AUTOSAR XML (schema 4-2-1)
standard types defined: boolean, float32, uint8, boolean_CompuMethod, boolean_DataConstr, float32_DataConstr, uint8_DataConstr
package /ComponentTypes
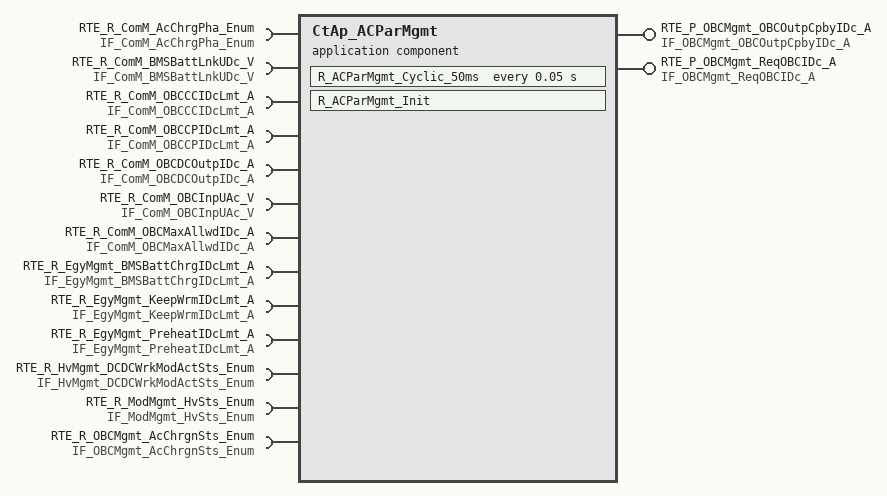
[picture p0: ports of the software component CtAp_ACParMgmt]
  application sw component type CtAp_ACParMgmt
    provide port RTE_P_OBCMgmt_OBCOutpCpbyIDc_A: nonqueued-sender-com-spec{data-element=tec_OBCMgmt_OBCOutpCpbyIDc_A, init-value=0}, provided-interface=IF_OBCMgmt_OBCOutpCpbyIDc_A
    provide port RTE_P_OBCMgmt_ReqOBCIDc_A: nonqueued-sender-com-spec{data-element=tec_OBCMgmt_ReqOBCIDc_A, init-value=0}, provided-interface=IF_OBCMgmt_ReqOBCIDc_A
    13 x require port:
      RTE_R_ComM_AcChrgPha_Enum: nonqueued-receiver-com-spec{data-element=tec_ComM_AcChrgPha_Enum, filter=data-filter-type=ALWAYS, init-value=0}, required-interface=IF_ComM_AcChrgPha_Enum
      RTE_R_ComM_BMSBattLnkUDc_V: nonqueued-receiver-com-spec{data-element=tec_ComM_BMSBattLnkUDc_V, filter=data-filter-type=ALWAYS, init-value=0}, required-interface=IF_ComM_BMSBattLnkUDc_V
      RTE_R_ComM_OBCCCIDcLmt_A: nonqueued-receiver-com-spec{data-element=tec_ComM_OBCCCIDcLmt_A, filter=data-filter-type=ALWAYS, init-value=0}, required-interface=IF_ComM_OBCCCIDcLmt_A
      RTE_R_ComM_OBCCPIDcLmt_A: nonqueued-receiver-com-spec{data-element=tec_ComM_OBCCPIDcLmt_A, filter=data-filter-type=ALWAYS, init-value=0}, required-interface=IF_ComM_OBCCPIDcLmt_A
      RTE_R_ComM_OBCDCOutpIDc_A: nonqueued-receiver-com-spec{data-element=tec_ComM_OBCDCOutpIDc_A, filter=data-filter-type=ALWAYS, init-value=0}, required-interface=IF_ComM_OBCDCOutpIDc_A
      RTE_R_ComM_OBCInpUAc_V: nonqueued-receiver-com-spec{data-element=tec_ComM_OBCInpUAc_V, filter=data-filter-type=ALWAYS, init-value=0}, required-interface=IF_ComM_OBCInpUAc_V
      RTE_R_ComM_OBCMaxAllwdIDc_A: nonqueued-receiver-com-spec{data-element=tec_ComM_OBCMaxAllwdIDc_A, filter=data-filter-type=ALWAYS, init-value=0}, required-interface=IF_ComM_OBCMaxAllwdIDc_A
      RTE_R_EgyMgmt_BMSBattChrgIDcLmt_A: nonqueued-receiver-com-spec{data-element=tec_EgyMgmt_BMSBattChrgIDcLmt_A, filter=data-filter-type=ALWAYS, init-value=0}, required-interface=IF_EgyMgmt_BMSBattChrgIDcLmt_A
      RTE_R_EgyMgmt_KeepWrmIDcLmt_A: nonqueued-receiver-com-spec{data-element=tec_EgyMgmt_KeepWrmIDcLmt_A, filter=data-filter-type=ALWAYS, init-value=0}, required-interface=IF_EgyMgmt_KeepWrmIDcLmt_A
      RTE_R_EgyMgmt_PreheatIDcLmt_A: nonqueued-receiver-com-spec{data-element=tec_EgyMgmt_PreheatIDcLmt_A, filter=data-filter-type=ALWAYS, init-value=0}, required-interface=IF_EgyMgmt_PreheatIDcLmt_A
      RTE_R_HvMgmt_DCDCWrkModActSts_Enum: nonqueued-receiver-com-spec{data-element=tec_HvMgmt_DCDCWrkModActSts_Enum, filter=data-filter-type=ALWAYS, init-value=0}, required-interface=IF_HvMgmt_DCDCWrkModActSts_Enum
      RTE_R_ModMgmt_HvSts_Enum: nonqueued-receiver-com-spec{data-element=tec_ModMgmt_HvSts_Enum, filter=data-filter-type=ALWAYS, init-value=0}, required-interface=IF_ModMgmt_HvSts_Enum
      RTE_R_OBCMgmt_AcChrgnSts_Enum: nonqueued-receiver-com-spec{data-element=tec_OBCMgmt_AcChrgnSts_Enum, filter=data-filter-type=ALWAYS, init-value=0}, required-interface=IF_OBCMgmt_AcChrgnSts_Enum
    behavior CtAp_ACParMgmt_InternalBehavior
      timing event TMT_R_ACParMgmt_Cyclic_50ms: start-on-event=R_ACParMgmt_Cyclic_50ms, period=0.05
      init event CtAp_ACParMgmt_InitEvent: start-on-event=R_ACParMgmt_Init
      runnable R_ACParMgmt_Cyclic_50ms
        data-receive-point-by-arguments:
          13 x access:
            REC_RTE_R_ComM_AcChrgPha_Enum_tec_ComM_AcChrgPha_Enum: accessed-variable=RTE_R_ComM_AcChrgPha_Enum.tec_ComM_AcChrgPha_Enum
            REC_RTE_R_ComM_BMSBattLnkUDc_V_tec_ComM_BMSBattLnkUDc_V: accessed-variable=RTE_R_ComM_BMSBattLnkUDc_V.tec_ComM_BMSBattLnkUDc_V
            REC_RTE_R_ComM_OBCCCIDcLmt_A_tec_ComM_OBCCCIDcLmt_A: accessed-variable=RTE_R_ComM_OBCCCIDcLmt_A.tec_ComM_OBCCCIDcLmt_A
            REC_RTE_R_ComM_OBCCPIDcLmt_A_tec_ComM_OBCCPIDcLmt_A: accessed-variable=RTE_R_ComM_OBCCPIDcLmt_A.tec_ComM_OBCCPIDcLmt_A
            REC_RTE_R_ComM_OBCDCOutpIDc_A_tec_ComM_OBCDCOutpIDc_A: accessed-variable=RTE_R_ComM_OBCDCOutpIDc_A.tec_ComM_OBCDCOutpIDc_A
            REC_RTE_R_ComM_OBCInpUAc_V_tec_ComM_OBCInpUAc_V: accessed-variable=RTE_R_ComM_OBCInpUAc_V.tec_ComM_OBCInpUAc_V
            REC_RTE_R_ComM_OBCMaxAllwdIDc_A_tec_ComM_OBCMaxAllwdIDc_A: accessed-variable=RTE_R_ComM_OBCMaxAllwdIDc_A.tec_ComM_OBCMaxAllwdIDc_A
            REC_RTE_R_EgyMgmt_BMSBattChrgIDcLmt_A_tec_EgyMgmt_BMSBattChrgIDcLmt_A: accessed-variable=RTE_R_EgyMgmt_BMSBattChrgIDcLmt_A.tec_EgyMgmt_BMSBattChrgIDcLmt_A
            REC_RTE_R_EgyMgmt_KeepWrmIDcLmt_A_tec_EgyMgmt_KeepWrmIDcLmt_A: accessed-variable=RTE_R_EgyMgmt_KeepWrmIDcLmt_A.tec_EgyMgmt_KeepWrmIDcLmt_A
            REC_RTE_R_EgyMgmt_PreheatIDcLmt_A_tec_EgyMgmt_PreheatIDcLmt_A: accessed-variable=RTE_R_EgyMgmt_PreheatIDcLmt_A.tec_EgyMgmt_PreheatIDcLmt_A
            REC_RTE_R_HvMgmt_DCDCWrkModActSts_Enum_tec_HvMgmt_DCDCWrkModActSts_Enum: accessed-variable=RTE_R_HvMgmt_DCDCWrkModActSts_Enum.tec_HvMgmt_DCDCWrkModActSts_Enum
            REC_RTE_R_ModMgmt_HvSts_Enum_tec_ModMgmt_HvSts_Enum: accessed-variable=RTE_R_ModMgmt_HvSts_Enum.tec_ModMgmt_HvSts_Enum
            REC_RTE_R_OBCMgmt_AcChrgnSts_Enum_tec_OBCMgmt_AcChrgnSts_Enum: accessed-variable=RTE_R_OBCMgmt_AcChrgnSts_Enum.tec_OBCMgmt_AcChrgnSts_Enum
        data-send-points:
          access SEND_RTE_P_OBCMgmt_OBCOutpCpbyIDc_A_tec_OBCMgmt_OBCOutpCpbyIDc_A: accessed-variable=RTE_P_OBCMgmt_OBCOutpCpbyIDc_A.tec_OBCMgmt_OBCOutpCpbyIDc_A
          access SEND_RTE_P_OBCMgmt_ReqOBCIDc_A_tec_OBCMgmt_ReqOBCIDc_A: accessed-variable=RTE_P_OBCMgmt_ReqOBCIDc_A.tec_OBCMgmt_ReqOBCIDc_A
      runnable R_ACParMgmt_Init
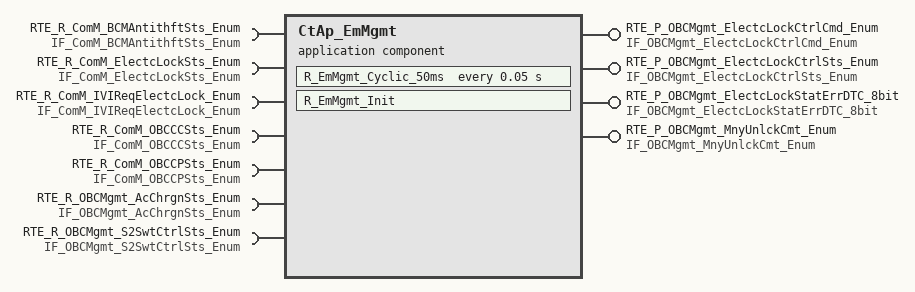
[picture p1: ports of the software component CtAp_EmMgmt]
  application sw component type CtAp_EmMgmt
    4 x provide port:
      RTE_P_OBCMgmt_ElectcLockCtrlCmd_Enum: nonqueued-sender-com-spec{data-element=tec_OBCMgmt_ElectcLockCtrlCmd_Enum, init-value=0}, provided-interface=IF_OBCMgmt_ElectcLockCtrlCmd_Enum
      RTE_P_OBCMgmt_ElectcLockCtrlSts_Enum: nonqueued-sender-com-spec{data-element=tec_OBCMgmt_ElectcLockCtrlSts_Enum, init-value=0}, provided-interface=IF_OBCMgmt_ElectcLockCtrlSts_Enum
      RTE_P_OBCMgmt_ElectcLockStatErrDTC_8bit: nonqueued-sender-com-spec{data-element=tec_OBCMgmt_ElectcLockStatErrDTC_8bit, init-value=0}, provided-interface=IF_OBCMgmt_ElectcLockStatErrDTC_8bit
      RTE_P_OBCMgmt_MnyUnlckCmt_Enum: nonqueued-sender-com-spec{data-element=tec_OBCMgmt_MnyUnlckCmt_Enum, init-value=0}, provided-interface=IF_OBCMgmt_MnyUnlckCmt_Enum
    7 x require port:
      RTE_R_ComM_BCMAntithftSts_Enum: nonqueued-receiver-com-spec{data-element=tec_ComM_BCMAntithftSts_Enum, filter=data-filter-type=ALWAYS, init-value=0}, required-interface=IF_ComM_BCMAntithftSts_Enum
      RTE_R_ComM_ElectcLockSts_Enum: nonqueued-receiver-com-spec{data-element=tec_ComM_ElectcLockSts_Enum, filter=data-filter-type=ALWAYS, init-value=0}, required-interface=IF_ComM_ElectcLockSts_Enum
      RTE_R_ComM_IVIReqElectcLock_Enum: nonqueued-receiver-com-spec{data-element=tec_ComM_IVIReqElectcLock_Enum, filter=data-filter-type=ALWAYS, init-value=0}, required-interface=IF_ComM_IVIReqElectcLock_Enum
      RTE_R_ComM_OBCCCSts_Enum: nonqueued-receiver-com-spec{data-element=tec_ComM_OBCCCSts_Enum, filter=data-filter-type=ALWAYS, init-value=0}, required-interface=IF_ComM_OBCCCSts_Enum
      RTE_R_ComM_OBCCPSts_Enum: nonqueued-receiver-com-spec{data-element=tec_ComM_OBCCPSts_Enum, filter=data-filter-type=ALWAYS, init-value=0}, required-interface=IF_ComM_OBCCPSts_Enum
      RTE_R_OBCMgmt_AcChrgnSts_Enum: nonqueued-receiver-com-spec{data-element=tec_OBCMgmt_AcChrgnSts_Enum, filter=data-filter-type=ALWAYS, init-value=0}, required-interface=IF_OBCMgmt_AcChrgnSts_Enum
      RTE_R_OBCMgmt_S2SwtCtrlSts_Enum: nonqueued-receiver-com-spec{data-element=tec_OBCMgmt_S2SwtCtrlSts_Enum, filter=data-filter-type=ALWAYS, init-value=0}, required-interface=IF_OBCMgmt_S2SwtCtrlSts_Enum
    behavior CtAp_EmMgmt_InternalBehavior
      timing event TMT_R_EmMgmt_Cyclic_50ms: start-on-event=R_EmMgmt_Cyclic_50ms, period=0.05
      init event CtAp_EmMgmt_InitEvent: start-on-event=R_EmMgmt_Init
      runnable R_EmMgmt_Cyclic_50ms
        data-receive-point-by-arguments:
          7 x access:
            REC_RTE_R_ComM_BCMAntithftSts_Enum_tec_ComM_BCMAntithftSts_Enum: accessed-variable=RTE_R_ComM_BCMAntithftSts_Enum.tec_ComM_BCMAntithftSts_Enum
            REC_RTE_R_ComM_ElectcLockSts_Enum_tec_ComM_ElectcLockSts_Enum: accessed-variable=RTE_R_ComM_ElectcLockSts_Enum.tec_ComM_ElectcLockSts_Enum
            REC_RTE_R_ComM_IVIReqElectcLock_Enum_tec_ComM_IVIReqElectcLock_Enum: accessed-variable=RTE_R_ComM_IVIReqElectcLock_Enum.tec_ComM_IVIReqElectcLock_Enum
            REC_RTE_R_ComM_OBCCCSts_Enum_tec_ComM_OBCCCSts_Enum: accessed-variable=RTE_R_ComM_OBCCCSts_Enum.tec_ComM_OBCCCSts_Enum
            REC_RTE_R_ComM_OBCCPSts_Enum_tec_ComM_OBCCPSts_Enum: accessed-variable=RTE_R_ComM_OBCCPSts_Enum.tec_ComM_OBCCPSts_Enum
            REC_RTE_R_OBCMgmt_AcChrgnSts_Enum_tec_OBCMgmt_AcChrgnSts_Enum: accessed-variable=RTE_R_OBCMgmt_AcChrgnSts_Enum.tec_OBCMgmt_AcChrgnSts_Enum
            REC_RTE_R_OBCMgmt_S2SwtCtrlSts_Enum_tec_OBCMgmt_S2SwtCtrlSts_Enum: accessed-variable=RTE_R_OBCMgmt_S2SwtCtrlSts_Enum.tec_OBCMgmt_S2SwtCtrlSts_Enum
        data-send-points:
          4 x access:
            SEND_RTE_P_OBCMgmt_ElectcLockCtrlCmd_Enum_tec_OBCMgmt_ElectcLockCtrlCmd_Enum: accessed-variable=RTE_P_OBCMgmt_ElectcLockCtrlCmd_Enum.tec_OBCMgmt_ElectcLockCtrlCmd_Enum
            SEND_RTE_P_OBCMgmt_ElectcLockCtrlSts_Enum_tec_OBCMgmt_ElectcLockCtrlSts_Enum: accessed-variable=RTE_P_OBCMgmt_ElectcLockCtrlSts_Enum.tec_OBCMgmt_ElectcLockCtrlSts_Enum
            SEND_RTE_P_OBCMgmt_ElectcLockStatErrDTC_8bit_tec_OBCMgmt_ElectcLockStatErrDTC_8bit: accessed-variable=RTE_P_OBCMgmt_ElectcLockStatErrDTC_8bit.tec_OBCMgmt_ElectcLockStatErrDTC_8bit
            SEND_RTE_P_OBCMgmt_MnyUnlckCmt_Enum_tec_OBCMgmt_MnyUnlckCmt_Enum: accessed-variable=RTE_P_OBCMgmt_MnyUnlckCmt_Enum.tec_OBCMgmt_MnyUnlckCmt_Enum
      runnable R_EmMgmt_Init
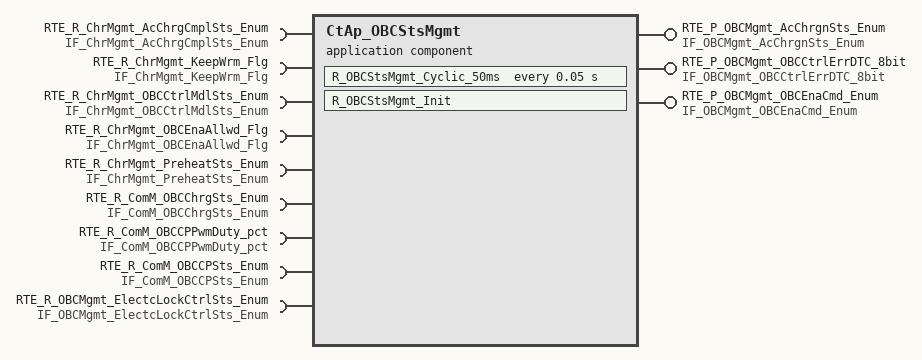
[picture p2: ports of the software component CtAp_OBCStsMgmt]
  application sw component type CtAp_OBCStsMgmt
    provide port RTE_P_OBCMgmt_AcChrgnSts_Enum: nonqueued-sender-com-spec{data-element=tec_OBCMgmt_AcChrgnSts_Enum, init-value=0}, provided-interface=IF_OBCMgmt_AcChrgnSts_Enum
    provide port RTE_P_OBCMgmt_OBCCtrlErrDTC_8bit: nonqueued-sender-com-spec{data-element=tec_OBCMgmt_OBCCtrlErrDTC_8bit, init-value=0}, provided-interface=IF_OBCMgmt_OBCCtrlErrDTC_8bit
    provide port RTE_P_OBCMgmt_OBCEnaCmd_Enum: nonqueued-sender-com-spec{data-element=tec_OBCMgmt_OBCEnaCmd_Enum, init-value=0}, provided-interface=IF_OBCMgmt_OBCEnaCmd_Enum
    9 x require port:
      RTE_R_ChrMgmt_AcChrgCmplSts_Enum: nonqueued-receiver-com-spec{data-element=tec_ChrMgmt_AcChrgCmplSts_Enum, filter=data-filter-type=ALWAYS, init-value=0}, required-interface=IF_ChrMgmt_AcChrgCmplSts_Enum
      RTE_R_ChrMgmt_KeepWrm_Flg: nonqueued-receiver-com-spec{data-element=tec_ChrMgmt_KeepWrm_Flg, filter=data-filter-type=ALWAYS, init-value=0}, required-interface=IF_ChrMgmt_KeepWrm_Flg
      RTE_R_ChrMgmt_OBCCtrlMdlSts_Enum: nonqueued-receiver-com-spec{data-element=tec_ChrMgmt_OBCCtrlMdlSts_Enum, filter=data-filter-type=ALWAYS, init-value=0}, required-interface=IF_ChrMgmt_OBCCtrlMdlSts_Enum
      RTE_R_ChrMgmt_OBCEnaAllwd_Flg: nonqueued-receiver-com-spec{data-element=tec_ChrMgmt_OBCEnaAllwd_Flg, filter=data-filter-type=ALWAYS, init-value=0}, required-interface=IF_ChrMgmt_OBCEnaAllwd_Flg
      RTE_R_ChrMgmt_PreheatSts_Enum: nonqueued-receiver-com-spec{data-element=tec_ChrMgmt_PreheatSts_Enum, filter=data-filter-type=ALWAYS, init-value=0}, required-interface=IF_ChrMgmt_PreheatSts_Enum
      RTE_R_ComM_OBCChrgSts_Enum: nonqueued-receiver-com-spec{data-element=tec_ComM_OBCChrgSts_Enum, filter=data-filter-type=ALWAYS, init-value=0}, required-interface=IF_ComM_OBCChrgSts_Enum
      RTE_R_ComM_OBCCPPwmDuty_pct: nonqueued-receiver-com-spec{data-element=tec_ComM_OBCCPPwmDuty_pct, filter=data-filter-type=ALWAYS, init-value=0}, required-interface=IF_ComM_OBCCPPwmDuty_pct
      RTE_R_ComM_OBCCPSts_Enum: nonqueued-receiver-com-spec{data-element=tec_ComM_OBCCPSts_Enum, filter=data-filter-type=ALWAYS, init-value=0}, required-interface=IF_ComM_OBCCPSts_Enum
      RTE_R_OBCMgmt_ElectcLockCtrlSts_Enum: nonqueued-receiver-com-spec{data-element=tec_OBCMgmt_ElectcLockCtrlSts_Enum, filter=data-filter-type=ALWAYS, init-value=0}, required-interface=IF_OBCMgmt_ElectcLockCtrlSts_Enum
    behavior CtAp_OBCStsMgmt_InternalBehavior
      timing event TMT_R_OBCStsMgmt_Cyclic_50ms: start-on-event=R_OBCStsMgmt_Cyclic_50ms, period=0.05
      init event CtAp_OBCStsMgmt_InitEvent: start-on-event=R_OBCStsMgmt_Init
      runnable R_OBCStsMgmt_Cyclic_50ms
        data-receive-point-by-arguments:
          9 x access:
            REC_RTE_R_ChrMgmt_AcChrgCmplSts_Enum_tec_ChrMgmt_AcChrgCmplSts_Enum: accessed-variable=RTE_R_ChrMgmt_AcChrgCmplSts_Enum.tec_ChrMgmt_AcChrgCmplSts_Enum
            REC_RTE_R_ChrMgmt_KeepWrm_Flg_tec_ChrMgmt_KeepWrm_Flg: accessed-variable=RTE_R_ChrMgmt_KeepWrm_Flg.tec_ChrMgmt_KeepWrm_Flg
            REC_RTE_R_ChrMgmt_OBCCtrlMdlSts_Enum_tec_ChrMgmt_OBCCtrlMdlSts_Enum: accessed-variable=RTE_R_ChrMgmt_OBCCtrlMdlSts_Enum.tec_ChrMgmt_OBCCtrlMdlSts_Enum
            REC_RTE_R_ChrMgmt_OBCEnaAllwd_Flg_tec_ChrMgmt_OBCEnaAllwd_Flg: accessed-variable=RTE_R_ChrMgmt_OBCEnaAllwd_Flg.tec_ChrMgmt_OBCEnaAllwd_Flg
            REC_RTE_R_ChrMgmt_PreheatSts_Enum_tec_ChrMgmt_PreheatSts_Enum: accessed-variable=RTE_R_ChrMgmt_PreheatSts_Enum.tec_ChrMgmt_PreheatSts_Enum
            REC_RTE_R_ComM_OBCChrgSts_Enum_tec_ComM_OBCChrgSts_Enum: accessed-variable=RTE_R_ComM_OBCChrgSts_Enum.tec_ComM_OBCChrgSts_Enum
            REC_RTE_R_ComM_OBCCPPwmDuty_pct_tec_ComM_OBCCPPwmDuty_pct: accessed-variable=RTE_R_ComM_OBCCPPwmDuty_pct.tec_ComM_OBCCPPwmDuty_pct
            REC_RTE_R_ComM_OBCCPSts_Enum_tec_ComM_OBCCPSts_Enum: accessed-variable=RTE_R_ComM_OBCCPSts_Enum.tec_ComM_OBCCPSts_Enum
            REC_RTE_R_OBCMgmt_ElectcLockCtrlSts_Enum_tec_OBCMgmt_ElectcLockCtrlSts_Enum: accessed-variable=RTE_R_OBCMgmt_ElectcLockCtrlSts_Enum.tec_OBCMgmt_ElectcLockCtrlSts_Enum
        data-send-points:
          access SEND_RTE_P_OBCMgmt_AcChrgnSts_Enum_tec_OBCMgmt_AcChrgnSts_Enum: accessed-variable=RTE_P_OBCMgmt_AcChrgnSts_Enum.tec_OBCMgmt_AcChrgnSts_Enum
          access SEND_RTE_P_OBCMgmt_OBCCtrlErrDTC_8bit_tec_OBCMgmt_OBCCtrlErrDTC_8bit: accessed-variable=RTE_P_OBCMgmt_OBCCtrlErrDTC_8bit.tec_OBCMgmt_OBCCtrlErrDTC_8bit
          access SEND_RTE_P_OBCMgmt_OBCEnaCmd_Enum_tec_OBCMgmt_OBCEnaCmd_Enum: accessed-variable=RTE_P_OBCMgmt_OBCEnaCmd_Enum.tec_OBCMgmt_OBCEnaCmd_Enum
      runnable R_OBCStsMgmt_Init
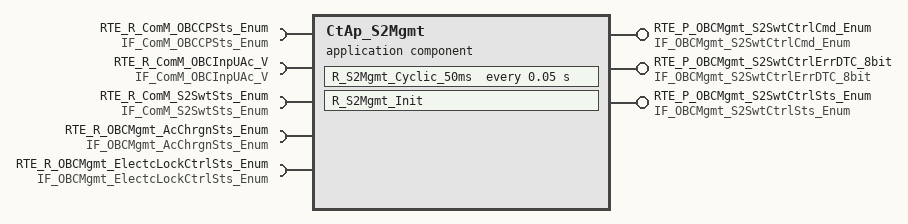
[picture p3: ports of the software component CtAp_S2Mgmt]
  application sw component type CtAp_S2Mgmt
    provide port RTE_P_OBCMgmt_S2SwtCtrlCmd_Enum: nonqueued-sender-com-spec{data-element=tec_OBCMgmt_S2SwtCtrlCmd_Enum, init-value=0}, provided-interface=IF_OBCMgmt_S2SwtCtrlCmd_Enum
    provide port RTE_P_OBCMgmt_S2SwtCtrlErrDTC_8bit: nonqueued-sender-com-spec{data-element=tec_OBCMgmt_S2SwtCtrlErrDTC_8bit, init-value=0}, provided-interface=IF_OBCMgmt_S2SwtCtrlErrDTC_8bit
    provide port RTE_P_OBCMgmt_S2SwtCtrlSts_Enum: nonqueued-sender-com-spec{data-element=tec_OBCMgmt_S2SwtCtrlSts_Enum, init-value=0}, provided-interface=IF_OBCMgmt_S2SwtCtrlSts_Enum
    5 x require port:
      RTE_R_ComM_OBCCPSts_Enum: nonqueued-receiver-com-spec{data-element=tec_ComM_OBCCPSts_Enum, filter=data-filter-type=ALWAYS, init-value=0}, required-interface=IF_ComM_OBCCPSts_Enum
      RTE_R_ComM_OBCInpUAc_V: nonqueued-receiver-com-spec{data-element=tec_ComM_OBCInpUAc_V, filter=data-filter-type=ALWAYS, init-value=0}, required-interface=IF_ComM_OBCInpUAc_V
      RTE_R_ComM_S2SwtSts_Enum: nonqueued-receiver-com-spec{data-element=tec_ComM_S2SwtSts_Enum, filter=data-filter-type=ALWAYS, init-value=0}, required-interface=IF_ComM_S2SwtSts_Enum
      RTE_R_OBCMgmt_AcChrgnSts_Enum: nonqueued-receiver-com-spec{data-element=tec_OBCMgmt_AcChrgnSts_Enum, filter=data-filter-type=ALWAYS, init-value=0}, required-interface=IF_OBCMgmt_AcChrgnSts_Enum
      RTE_R_OBCMgmt_ElectcLockCtrlSts_Enum: nonqueued-receiver-com-spec{data-element=tec_OBCMgmt_ElectcLockCtrlSts_Enum, filter=data-filter-type=ALWAYS, init-value=0}, required-interface=IF_OBCMgmt_ElectcLockCtrlSts_Enum
    behavior CtAp_S2Mgmt_InternalBehavior
      timing event TMT_R_S2Mgmt_Cyclic_50ms: start-on-event=R_S2Mgmt_Cyclic_50ms, period=0.05
      init event CtAp_S2Mgmt_InitEvent: start-on-event=R_S2Mgmt_Init
      runnable R_S2Mgmt_Cyclic_50ms
        data-receive-point-by-arguments:
          5 x access:
            REC_RTE_R_ComM_OBCCPSts_Enum_tec_ComM_OBCCPSts_Enum: accessed-variable=RTE_R_ComM_OBCCPSts_Enum.tec_ComM_OBCCPSts_Enum
            REC_RTE_R_ComM_OBCInpUAc_V_tec_ComM_OBCInpUAc_V: accessed-variable=RTE_R_ComM_OBCInpUAc_V.tec_ComM_OBCInpUAc_V
            REC_RTE_R_ComM_S2SwtSts_Enum_tec_ComM_S2SwtSts_Enum: accessed-variable=RTE_R_ComM_S2SwtSts_Enum.tec_ComM_S2SwtSts_Enum
            REC_RTE_R_OBCMgmt_AcChrgnSts_Enum_tec_OBCMgmt_AcChrgnSts_Enum: accessed-variable=RTE_R_OBCMgmt_AcChrgnSts_Enum.tec_OBCMgmt_AcChrgnSts_Enum
            REC_RTE_R_OBCMgmt_ElectcLockCtrlSts_Enum_tec_OBCMgmt_ElectcLockCtrlSts_Enum: accessed-variable=RTE_R_OBCMgmt_ElectcLockCtrlSts_Enum.tec_OBCMgmt_ElectcLockCtrlSts_Enum
        data-send-points:
          access SEND_RTE_P_OBCMgmt_S2SwtCtrlCmd_Enum_tec_OBCMgmt_S2SwtCtrlCmd_Enum: accessed-variable=RTE_P_OBCMgmt_S2SwtCtrlCmd_Enum.tec_OBCMgmt_S2SwtCtrlCmd_Enum
          access SEND_RTE_P_OBCMgmt_S2SwtCtrlErrDTC_8bit_tec_OBCMgmt_S2SwtCtrlErrDTC_8bit: accessed-variable=RTE_P_OBCMgmt_S2SwtCtrlErrDTC_8bit.tec_OBCMgmt_S2SwtCtrlErrDTC_8bit
          access SEND_RTE_P_OBCMgmt_S2SwtCtrlSts_Enum_tec_OBCMgmt_S2SwtCtrlSts_Enum: accessed-variable=RTE_P_OBCMgmt_S2SwtCtrlSts_Enum.tec_OBCMgmt_S2SwtCtrlSts_Enum
      runnable R_S2Mgmt_Init
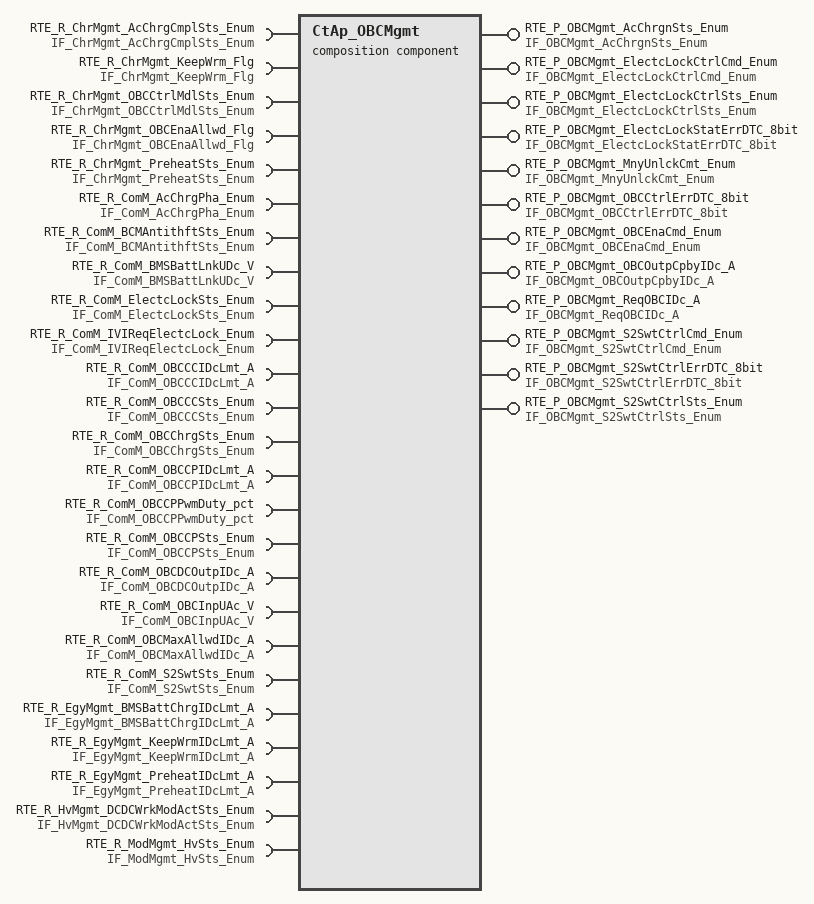
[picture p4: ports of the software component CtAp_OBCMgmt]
  composition sw component type CtAp_OBCMgmt
    12 x provide port:
      RTE_P_OBCMgmt_AcChrgnSts_Enum: nonqueued-sender-com-spec{data-element=tec_OBCMgmt_AcChrgnSts_Enum, init-value=0}, provided-interface=IF_OBCMgmt_AcChrgnSts_Enum
      RTE_P_OBCMgmt_ElectcLockCtrlCmd_Enum: nonqueued-sender-com-spec{data-element=tec_OBCMgmt_ElectcLockCtrlCmd_Enum, init-value=0}, provided-interface=IF_OBCMgmt_ElectcLockCtrlCmd_Enum
      RTE_P_OBCMgmt_ElectcLockCtrlSts_Enum: nonqueued-sender-com-spec{data-element=tec_OBCMgmt_ElectcLockCtrlSts_Enum, init-value=0}, provided-interface=IF_OBCMgmt_ElectcLockCtrlSts_Enum
      RTE_P_OBCMgmt_ElectcLockStatErrDTC_8bit: nonqueued-sender-com-spec{data-element=tec_OBCMgmt_ElectcLockStatErrDTC_8bit, init-value=0}, provided-interface=IF_OBCMgmt_ElectcLockStatErrDTC_8bit
      RTE_P_OBCMgmt_MnyUnlckCmt_Enum: nonqueued-sender-com-spec{data-element=tec_OBCMgmt_MnyUnlckCmt_Enum, init-value=0}, provided-interface=IF_OBCMgmt_MnyUnlckCmt_Enum
      RTE_P_OBCMgmt_OBCCtrlErrDTC_8bit: nonqueued-sender-com-spec{data-element=tec_OBCMgmt_OBCCtrlErrDTC_8bit, init-value=0}, provided-interface=IF_OBCMgmt_OBCCtrlErrDTC_8bit
      RTE_P_OBCMgmt_OBCEnaCmd_Enum: nonqueued-sender-com-spec{data-element=tec_OBCMgmt_OBCEnaCmd_Enum, init-value=0}, provided-interface=IF_OBCMgmt_OBCEnaCmd_Enum
      RTE_P_OBCMgmt_OBCOutpCpbyIDc_A: nonqueued-sender-com-spec{data-element=tec_OBCMgmt_OBCOutpCpbyIDc_A, init-value=0}, provided-interface=IF_OBCMgmt_OBCOutpCpbyIDc_A
      RTE_P_OBCMgmt_ReqOBCIDc_A: nonqueued-sender-com-spec{data-element=tec_OBCMgmt_ReqOBCIDc_A, init-value=0}, provided-interface=IF_OBCMgmt_ReqOBCIDc_A
      RTE_P_OBCMgmt_S2SwtCtrlCmd_Enum: nonqueued-sender-com-spec{data-element=tec_OBCMgmt_S2SwtCtrlCmd_Enum, init-value=0}, provided-interface=IF_OBCMgmt_S2SwtCtrlCmd_Enum
      RTE_P_OBCMgmt_S2SwtCtrlErrDTC_8bit: nonqueued-sender-com-spec{data-element=tec_OBCMgmt_S2SwtCtrlErrDTC_8bit, init-value=0}, provided-interface=IF_OBCMgmt_S2SwtCtrlErrDTC_8bit
      RTE_P_OBCMgmt_S2SwtCtrlSts_Enum: nonqueued-sender-com-spec{data-element=tec_OBCMgmt_S2SwtCtrlSts_Enum, init-value=0}, provided-interface=IF_OBCMgmt_S2SwtCtrlSts_Enum
    25 x require port:
      RTE_R_ChrMgmt_AcChrgCmplSts_Enum: nonqueued-receiver-com-spec{data-element=tec_ChrMgmt_AcChrgCmplSts_Enum, filter=data-filter-type=ALWAYS, init-value=0}, required-interface=IF_ChrMgmt_AcChrgCmplSts_Enum
      RTE_R_ChrMgmt_KeepWrm_Flg: nonqueued-receiver-com-spec{data-element=tec_ChrMgmt_KeepWrm_Flg, filter=data-filter-type=ALWAYS, init-value=0}, required-interface=IF_ChrMgmt_KeepWrm_Flg
      RTE_R_ChrMgmt_OBCCtrlMdlSts_Enum: nonqueued-receiver-com-spec{data-element=tec_ChrMgmt_OBCCtrlMdlSts_Enum, filter=data-filter-type=ALWAYS, init-value=0}, required-interface=IF_ChrMgmt_OBCCtrlMdlSts_Enum
      RTE_R_ChrMgmt_OBCEnaAllwd_Flg: nonqueued-receiver-com-spec{data-element=tec_ChrMgmt_OBCEnaAllwd_Flg, filter=data-filter-type=ALWAYS, init-value=0}, required-interface=IF_ChrMgmt_OBCEnaAllwd_Flg
      RTE_R_ChrMgmt_PreheatSts_Enum: nonqueued-receiver-com-spec{data-element=tec_ChrMgmt_PreheatSts_Enum, filter=data-filter-type=ALWAYS, init-value=0}, required-interface=IF_ChrMgmt_PreheatSts_Enum
      RTE_R_ComM_AcChrgPha_Enum: nonqueued-receiver-com-spec{data-element=tec_ComM_AcChrgPha_Enum, filter=data-filter-type=ALWAYS, init-value=0}, required-interface=IF_ComM_AcChrgPha_Enum
      RTE_R_ComM_BCMAntithftSts_Enum: nonqueued-receiver-com-spec{data-element=tec_ComM_BCMAntithftSts_Enum, filter=data-filter-type=ALWAYS, init-value=0}, required-interface=IF_ComM_BCMAntithftSts_Enum
      RTE_R_ComM_BMSBattLnkUDc_V: nonqueued-receiver-com-spec{data-element=tec_ComM_BMSBattLnkUDc_V, filter=data-filter-type=ALWAYS, init-value=0}, required-interface=IF_ComM_BMSBattLnkUDc_V
      RTE_R_ComM_ElectcLockSts_Enum: nonqueued-receiver-com-spec{data-element=tec_ComM_ElectcLockSts_Enum, filter=data-filter-type=ALWAYS, init-value=0}, required-interface=IF_ComM_ElectcLockSts_Enum
      RTE_R_ComM_IVIReqElectcLock_Enum: nonqueued-receiver-com-spec{data-element=tec_ComM_IVIReqElectcLock_Enum, filter=data-filter-type=ALWAYS, init-value=0}, required-interface=IF_ComM_IVIReqElectcLock_Enum
      RTE_R_ComM_OBCCCIDcLmt_A: nonqueued-receiver-com-spec{data-element=tec_ComM_OBCCCIDcLmt_A, filter=data-filter-type=ALWAYS, init-value=0}, required-interface=IF_ComM_OBCCCIDcLmt_A
      RTE_R_ComM_OBCCCSts_Enum: nonqueued-receiver-com-spec{data-element=tec_ComM_OBCCCSts_Enum, filter=data-filter-type=ALWAYS, init-value=0}, required-interface=IF_ComM_OBCCCSts_Enum
      RTE_R_ComM_OBCChrgSts_Enum: nonqueued-receiver-com-spec{data-element=tec_ComM_OBCChrgSts_Enum, filter=data-filter-type=ALWAYS, init-value=0}, required-interface=IF_ComM_OBCChrgSts_Enum
      RTE_R_ComM_OBCCPIDcLmt_A: nonqueued-receiver-com-spec{data-element=tec_ComM_OBCCPIDcLmt_A, filter=data-filter-type=ALWAYS, init-value=0}, required-interface=IF_ComM_OBCCPIDcLmt_A
      RTE_R_ComM_OBCCPPwmDuty_pct: nonqueued-receiver-com-spec{data-element=tec_ComM_OBCCPPwmDuty_pct, filter=data-filter-type=ALWAYS, init-value=0}, required-interface=IF_ComM_OBCCPPwmDuty_pct
      RTE_R_ComM_OBCCPSts_Enum: nonqueued-receiver-com-spec{data-element=tec_ComM_OBCCPSts_Enum, filter=data-filter-type=ALWAYS, init-value=0}, required-interface=IF_ComM_OBCCPSts_Enum
      RTE_R_ComM_OBCDCOutpIDc_A: nonqueued-receiver-com-spec{data-element=tec_ComM_OBCDCOutpIDc_A, filter=data-filter-type=ALWAYS, init-value=0}, required-interface=IF_ComM_OBCDCOutpIDc_A
      RTE_R_ComM_OBCInpUAc_V: nonqueued-receiver-com-spec{data-element=tec_ComM_OBCInpUAc_V, filter=data-filter-type=ALWAYS, init-value=0}, required-interface=IF_ComM_OBCInpUAc_V
      RTE_R_ComM_OBCMaxAllwdIDc_A: nonqueued-receiver-com-spec{data-element=tec_ComM_OBCMaxAllwdIDc_A, filter=data-filter-type=ALWAYS, init-value=0}, required-interface=IF_ComM_OBCMaxAllwdIDc_A
      RTE_R_ComM_S2SwtSts_Enum: nonqueued-receiver-com-spec{data-element=tec_ComM_S2SwtSts_Enum, filter=data-filter-type=ALWAYS, init-value=0}, required-interface=IF_ComM_S2SwtSts_Enum
      RTE_R_EgyMgmt_BMSBattChrgIDcLmt_A: nonqueued-receiver-com-spec{data-element=tec_EgyMgmt_BMSBattChrgIDcLmt_A, filter=data-filter-type=ALWAYS, init-value=0}, required-interface=IF_EgyMgmt_BMSBattChrgIDcLmt_A
      RTE_R_EgyMgmt_KeepWrmIDcLmt_A: nonqueued-receiver-com-spec{data-element=tec_EgyMgmt_KeepWrmIDcLmt_A, filter=data-filter-type=ALWAYS, init-value=0}, required-interface=IF_EgyMgmt_KeepWrmIDcLmt_A
      RTE_R_EgyMgmt_PreheatIDcLmt_A: nonqueued-receiver-com-spec{data-element=tec_EgyMgmt_PreheatIDcLmt_A, filter=data-filter-type=ALWAYS, init-value=0}, required-interface=IF_EgyMgmt_PreheatIDcLmt_A
      RTE_R_HvMgmt_DCDCWrkModActSts_Enum: nonqueued-receiver-com-spec{data-element=tec_HvMgmt_DCDCWrkModActSts_Enum, filter=data-filter-type=ALWAYS, init-value=0}, required-interface=IF_HvMgmt_DCDCWrkModActSts_Enum
      RTE_R_ModMgmt_HvSts_Enum: nonqueued-receiver-com-spec{data-element=tec_ModMgmt_HvSts_Enum, filter=data-filter-type=ALWAYS, init-value=0}, required-interface=IF_ModMgmt_HvSts_Enum
    4 x component:
      CtAp_ACParMgmt: type=CtAp_ACParMgmt
      CtAp_EmMgmt: type=CtAp_EmMgmt
      CtAp_OBCStsMgmt: type=CtAp_OBCStsMgmt
      CtAp_S2Mgmt: type=CtAp_S2Mgmt
    connect CtAp_EmMgmt.RTE_P_OBCMgmt_ElectcLockCtrlSts_Enum -> CtAp_OBCStsMgmt.RTE_R_OBCMgmt_ElectcLockCtrlSts_Enum
    connect CtAp_EmMgmt.RTE_P_OBCMgmt_ElectcLockCtrlSts_Enum -> CtAp_S2Mgmt.RTE_R_OBCMgmt_ElectcLockCtrlSts_Enum
    connect CtAp_OBCStsMgmt.RTE_P_OBCMgmt_AcChrgnSts_Enum -> CtAp_ACParMgmt.RTE_R_OBCMgmt_AcChrgnSts_Enum
    connect CtAp_OBCStsMgmt.RTE_P_OBCMgmt_AcChrgnSts_Enum -> CtAp_EmMgmt.RTE_R_OBCMgmt_AcChrgnSts_Enum
    connect CtAp_OBCStsMgmt.RTE_P_OBCMgmt_AcChrgnSts_Enum -> CtAp_S2Mgmt.RTE_R_OBCMgmt_AcChrgnSts_Enum
    connect CtAp_S2Mgmt.RTE_P_OBCMgmt_S2SwtCtrlSts_Enum -> CtAp_EmMgmt.RTE_R_OBCMgmt_S2SwtCtrlSts_Enum
    delegate CtAp_OBCStsMgmt.RTE_P_OBCMgmt_AcChrgnSts_Enum <-> outer port CtAp_OBCMgmt/RTE_P_OBCMgmt_AcChrgnSts_Enum
    delegate CtAp_EmMgmt.RTE_P_OBCMgmt_ElectcLockCtrlCmd_Enum <-> outer port CtAp_OBCMgmt/RTE_P_OBCMgmt_ElectcLockCtrlCmd_Enum
    delegate CtAp_EmMgmt.RTE_P_OBCMgmt_ElectcLockCtrlSts_Enum <-> outer port CtAp_OBCMgmt/RTE_P_OBCMgmt_ElectcLockCtrlSts_Enum
    delegate CtAp_EmMgmt.RTE_P_OBCMgmt_ElectcLockStatErrDTC_8bit <-> outer port CtAp_OBCMgmt/RTE_P_OBCMgmt_ElectcLockStatErrDTC_8bit
    delegate CtAp_EmMgmt.RTE_P_OBCMgmt_MnyUnlckCmt_Enum <-> outer port CtAp_OBCMgmt/RTE_P_OBCMgmt_MnyUnlckCmt_Enum
    delegate CtAp_OBCStsMgmt.RTE_P_OBCMgmt_OBCCtrlErrDTC_8bit <-> outer port CtAp_OBCMgmt/RTE_P_OBCMgmt_OBCCtrlErrDTC_8bit
    delegate CtAp_OBCStsMgmt.RTE_P_OBCMgmt_OBCEnaCmd_Enum <-> outer port CtAp_OBCMgmt/RTE_P_OBCMgmt_OBCEnaCmd_Enum
    delegate CtAp_ACParMgmt.RTE_P_OBCMgmt_OBCOutpCpbyIDc_A <-> outer port CtAp_OBCMgmt/RTE_P_OBCMgmt_OBCOutpCpbyIDc_A
    delegate CtAp_ACParMgmt.RTE_P_OBCMgmt_ReqOBCIDc_A <-> outer port CtAp_OBCMgmt/RTE_P_OBCMgmt_ReqOBCIDc_A
    delegate CtAp_S2Mgmt.RTE_P_OBCMgmt_S2SwtCtrlCmd_Enum <-> outer port CtAp_OBCMgmt/RTE_P_OBCMgmt_S2SwtCtrlCmd_Enum
    delegate CtAp_S2Mgmt.RTE_P_OBCMgmt_S2SwtCtrlErrDTC_8bit <-> outer port CtAp_OBCMgmt/RTE_P_OBCMgmt_S2SwtCtrlErrDTC_8bit
    delegate CtAp_S2Mgmt.RTE_P_OBCMgmt_S2SwtCtrlSts_Enum <-> outer port CtAp_OBCMgmt/RTE_P_OBCMgmt_S2SwtCtrlSts_Enum
    delegate CtAp_OBCStsMgmt.RTE_R_ChrMgmt_AcChrgCmplSts_Enum <-> outer port CtAp_OBCMgmt/RTE_R_ChrMgmt_AcChrgCmplSts_Enum
    delegate CtAp_OBCStsMgmt.RTE_R_ChrMgmt_KeepWrm_Flg <-> outer port CtAp_OBCMgmt/RTE_R_ChrMgmt_KeepWrm_Flg
    delegate CtAp_OBCStsMgmt.RTE_R_ChrMgmt_OBCCtrlMdlSts_Enum <-> outer port CtAp_OBCMgmt/RTE_R_ChrMgmt_OBCCtrlMdlSts_Enum
    delegate CtAp_OBCStsMgmt.RTE_R_ChrMgmt_OBCEnaAllwd_Flg <-> outer port CtAp_OBCMgmt/RTE_R_ChrMgmt_OBCEnaAllwd_Flg
    delegate CtAp_OBCStsMgmt.RTE_R_ChrMgmt_PreheatSts_Enum <-> outer port CtAp_OBCMgmt/RTE_R_ChrMgmt_PreheatSts_Enum
    delegate CtAp_ACParMgmt.RTE_R_ComM_AcChrgPha_Enum <-> outer port CtAp_OBCMgmt/RTE_R_ComM_AcChrgPha_Enum
    delegate CtAp_EmMgmt.RTE_R_ComM_BCMAntithftSts_Enum <-> outer port CtAp_OBCMgmt/RTE_R_ComM_BCMAntithftSts_Enum
    delegate CtAp_ACParMgmt.RTE_R_ComM_BMSBattLnkUDc_V <-> outer port CtAp_OBCMgmt/RTE_R_ComM_BMSBattLnkUDc_V
    delegate CtAp_EmMgmt.RTE_R_ComM_ElectcLockSts_Enum <-> outer port CtAp_OBCMgmt/RTE_R_ComM_ElectcLockSts_Enum
    delegate CtAp_EmMgmt.RTE_R_ComM_IVIReqElectcLock_Enum <-> outer port CtAp_OBCMgmt/RTE_R_ComM_IVIReqElectcLock_Enum
    delegate CtAp_ACParMgmt.RTE_R_ComM_OBCCCIDcLmt_A <-> outer port CtAp_OBCMgmt/RTE_R_ComM_OBCCCIDcLmt_A
    delegate CtAp_EmMgmt.RTE_R_ComM_OBCCCSts_Enum <-> outer port CtAp_OBCMgmt/RTE_R_ComM_OBCCCSts_Enum
    delegate CtAp_OBCStsMgmt.RTE_R_ComM_OBCChrgSts_Enum <-> outer port CtAp_OBCMgmt/RTE_R_ComM_OBCChrgSts_Enum
    delegate CtAp_ACParMgmt.RTE_R_ComM_OBCCPIDcLmt_A <-> outer port CtAp_OBCMgmt/RTE_R_ComM_OBCCPIDcLmt_A
    delegate CtAp_OBCStsMgmt.RTE_R_ComM_OBCCPPwmDuty_pct <-> outer port CtAp_OBCMgmt/RTE_R_ComM_OBCCPPwmDuty_pct
    delegate CtAp_EmMgmt.RTE_R_ComM_OBCCPSts_Enum <-> outer port CtAp_OBCMgmt/RTE_R_ComM_OBCCPSts_Enum
    delegate CtAp_OBCStsMgmt.RTE_R_ComM_OBCCPSts_Enum <-> outer port CtAp_OBCMgmt/RTE_R_ComM_OBCCPSts_Enum
    delegate CtAp_S2Mgmt.RTE_R_ComM_OBCCPSts_Enum <-> outer port CtAp_OBCMgmt/RTE_R_ComM_OBCCPSts_Enum
    delegate CtAp_ACParMgmt.RTE_R_ComM_OBCDCOutpIDc_A <-> outer port CtAp_OBCMgmt/RTE_R_ComM_OBCDCOutpIDc_A
    delegate CtAp_ACParMgmt.RTE_R_ComM_OBCInpUAc_V <-> outer port CtAp_OBCMgmt/RTE_R_ComM_OBCInpUAc_V
    delegate CtAp_S2Mgmt.RTE_R_ComM_OBCInpUAc_V <-> outer port CtAp_OBCMgmt/RTE_R_ComM_OBCInpUAc_V
    delegate CtAp_ACParMgmt.RTE_R_ComM_OBCMaxAllwdIDc_A <-> outer port CtAp_OBCMgmt/RTE_R_ComM_OBCMaxAllwdIDc_A
    delegate CtAp_S2Mgmt.RTE_R_ComM_S2SwtSts_Enum <-> outer port CtAp_OBCMgmt/RTE_R_ComM_S2SwtSts_Enum
    delegate CtAp_ACParMgmt.RTE_R_EgyMgmt_BMSBattChrgIDcLmt_A <-> outer port CtAp_OBCMgmt/RTE_R_EgyMgmt_BMSBattChrgIDcLmt_A
    delegate CtAp_ACParMgmt.RTE_R_EgyMgmt_KeepWrmIDcLmt_A <-> outer port CtAp_OBCMgmt/RTE_R_EgyMgmt_KeepWrmIDcLmt_A
    delegate CtAp_ACParMgmt.RTE_R_EgyMgmt_PreheatIDcLmt_A <-> outer port CtAp_OBCMgmt/RTE_R_EgyMgmt_PreheatIDcLmt_A
    delegate CtAp_ACParMgmt.RTE_R_HvMgmt_DCDCWrkModActSts_Enum <-> outer port CtAp_OBCMgmt/RTE_R_HvMgmt_DCDCWrkModActSts_Enum
    delegate CtAp_ACParMgmt.RTE_R_ModMgmt_HvSts_Enum <-> outer port CtAp_OBCMgmt/RTE_R_ModMgmt_HvSts_Enum
  4 x swc implementation:
    CtAp_ACParMgmt_Implementation: behavior=CtAp_ACParMgmt_InternalBehavior
      code-descriptors:
        code Default: artifact-descriptors=autosar-engineering-object={short-label=Default, category=SWOBJ}
    CtAp_EmMgmt_Implementation: behavior=CtAp_EmMgmt_InternalBehavior
      code-descriptors:
        code Default: artifact-descriptors=autosar-engineering-object={short-label=Default, category=SWOBJ}
    CtAp_OBCStsMgmt_Implementation: behavior=CtAp_OBCStsMgmt_InternalBehavior
      code-descriptors:
        code Default: artifact-descriptors=autosar-engineering-object={short-label=Default, category=SWOBJ}
    CtAp_S2Mgmt_Implementation: behavior=CtAp_S2Mgmt_InternalBehavior
      code-descriptors:
        code Default: artifact-descriptors=autosar-engineering-object={short-label=Default, category=SWOBJ}
package /PortInterfaces
  37 x sender receiver interface:
    IF_ChrMgmt_AcChrgCmplSts_Enum: invalidation-policy{data-element=tec_ChrMgmt_AcChrgCmplSts_Enum, handle-invalid=DONT-INVALIDATE}
      data tec_ChrMgmt_AcChrgCmplSts_Enum: type=uint8
    IF_ChrMgmt_KeepWrm_Flg: invalidation-policy{data-element=tec_ChrMgmt_KeepWrm_Flg, handle-invalid=DONT-INVALIDATE}
      data tec_ChrMgmt_KeepWrm_Flg: type=boolean
    IF_ChrMgmt_OBCCtrlMdlSts_Enum: invalidation-policy{data-element=tec_ChrMgmt_OBCCtrlMdlSts_Enum, handle-invalid=DONT-INVALIDATE}
      data tec_ChrMgmt_OBCCtrlMdlSts_Enum: type=uint8
    IF_ChrMgmt_OBCEnaAllwd_Flg: invalidation-policy{data-element=tec_ChrMgmt_OBCEnaAllwd_Flg, handle-invalid=DONT-INVALIDATE}
      data tec_ChrMgmt_OBCEnaAllwd_Flg: type=boolean
    IF_ChrMgmt_PreheatSts_Enum: invalidation-policy{data-element=tec_ChrMgmt_PreheatSts_Enum, handle-invalid=DONT-INVALIDATE}
      data tec_ChrMgmt_PreheatSts_Enum: type=uint8
    IF_ComM_AcChrgPha_Enum: invalidation-policy{data-element=tec_ComM_AcChrgPha_Enum, handle-invalid=DONT-INVALIDATE}
      data tec_ComM_AcChrgPha_Enum: type=uint8
    IF_ComM_BCMAntithftSts_Enum: invalidation-policy{data-element=tec_ComM_BCMAntithftSts_Enum, handle-invalid=DONT-INVALIDATE}
      data tec_ComM_BCMAntithftSts_Enum: type=uint8
    IF_ComM_BMSBattLnkUDc_V: invalidation-policy{data-element=tec_ComM_BMSBattLnkUDc_V, handle-invalid=DONT-INVALIDATE}
      data tec_ComM_BMSBattLnkUDc_V: type=float32
    IF_ComM_ElectcLockSts_Enum: invalidation-policy{data-element=tec_ComM_ElectcLockSts_Enum, handle-invalid=DONT-INVALIDATE}
      data tec_ComM_ElectcLockSts_Enum: type=uint8
    IF_ComM_IVIReqElectcLock_Enum: invalidation-policy{data-element=tec_ComM_IVIReqElectcLock_Enum, handle-invalid=DONT-INVALIDATE}
      data tec_ComM_IVIReqElectcLock_Enum: type=uint8
    IF_ComM_OBCCCIDcLmt_A: invalidation-policy{data-element=tec_ComM_OBCCCIDcLmt_A, handle-invalid=DONT-INVALIDATE}
      data tec_ComM_OBCCCIDcLmt_A: type=float32
    IF_ComM_OBCCCSts_Enum: invalidation-policy{data-element=tec_ComM_OBCCCSts_Enum, handle-invalid=DONT-INVALIDATE}
      data tec_ComM_OBCCCSts_Enum: type=uint8
    IF_ComM_OBCChrgSts_Enum: invalidation-policy{data-element=tec_ComM_OBCChrgSts_Enum, handle-invalid=DONT-INVALIDATE}
      data tec_ComM_OBCChrgSts_Enum: type=uint8
    IF_ComM_OBCCPIDcLmt_A: invalidation-policy{data-element=tec_ComM_OBCCPIDcLmt_A, handle-invalid=DONT-INVALIDATE}
      data tec_ComM_OBCCPIDcLmt_A: type=float32
    IF_ComM_OBCCPPwmDuty_pct: invalidation-policy{data-element=tec_ComM_OBCCPPwmDuty_pct, handle-invalid=DONT-INVALIDATE}
      data tec_ComM_OBCCPPwmDuty_pct: type=uint8
    IF_ComM_OBCCPSts_Enum: invalidation-policy{data-element=tec_ComM_OBCCPSts_Enum, handle-invalid=DONT-INVALIDATE}
      data tec_ComM_OBCCPSts_Enum: type=uint8
    IF_ComM_OBCDCOutpIDc_A: invalidation-policy{data-element=tec_ComM_OBCDCOutpIDc_A, handle-invalid=DONT-INVALIDATE}
      data tec_ComM_OBCDCOutpIDc_A: type=float32
    IF_ComM_OBCInpUAc_V: invalidation-policy{data-element=tec_ComM_OBCInpUAc_V, handle-invalid=DONT-INVALIDATE}
      data tec_ComM_OBCInpUAc_V: type=float32
    IF_ComM_OBCMaxAllwdIDc_A: invalidation-policy{data-element=tec_ComM_OBCMaxAllwdIDc_A, handle-invalid=DONT-INVALIDATE}
      data tec_ComM_OBCMaxAllwdIDc_A: type=float32
    IF_ComM_S2SwtSts_Enum: invalidation-policy{data-element=tec_ComM_S2SwtSts_Enum, handle-invalid=DONT-INVALIDATE}
      data tec_ComM_S2SwtSts_Enum: type=uint8
    IF_EgyMgmt_BMSBattChrgIDcLmt_A: invalidation-policy{data-element=tec_EgyMgmt_BMSBattChrgIDcLmt_A, handle-invalid=DONT-INVALIDATE}
      data tec_EgyMgmt_BMSBattChrgIDcLmt_A: type=float32
    IF_EgyMgmt_KeepWrmIDcLmt_A: invalidation-policy{data-element=tec_EgyMgmt_KeepWrmIDcLmt_A, handle-invalid=DONT-INVALIDATE}
      data tec_EgyMgmt_KeepWrmIDcLmt_A: type=float32
    IF_EgyMgmt_PreheatIDcLmt_A: invalidation-policy{data-element=tec_EgyMgmt_PreheatIDcLmt_A, handle-invalid=DONT-INVALIDATE}
      data tec_EgyMgmt_PreheatIDcLmt_A: type=float32
    IF_HvMgmt_DCDCWrkModActSts_Enum: invalidation-policy{data-element=tec_HvMgmt_DCDCWrkModActSts_Enum, handle-invalid=DONT-INVALIDATE}
      data tec_HvMgmt_DCDCWrkModActSts_Enum: type=uint8
    IF_ModMgmt_HvSts_Enum: invalidation-policy{data-element=tec_ModMgmt_HvSts_Enum, handle-invalid=DONT-INVALIDATE}
      data tec_ModMgmt_HvSts_Enum: type=uint8
    IF_OBCMgmt_AcChrgnSts_Enum: invalidation-policy{data-element=tec_OBCMgmt_AcChrgnSts_Enum, handle-invalid=DONT-INVALIDATE}
      data tec_OBCMgmt_AcChrgnSts_Enum: type=uint8
    IF_OBCMgmt_ElectcLockCtrlCmd_Enum: invalidation-policy{data-element=tec_OBCMgmt_ElectcLockCtrlCmd_Enum, handle-invalid=DONT-INVALIDATE}
      data tec_OBCMgmt_ElectcLockCtrlCmd_Enum: type=uint8
    IF_OBCMgmt_ElectcLockCtrlSts_Enum: invalidation-policy{data-element=tec_OBCMgmt_ElectcLockCtrlSts_Enum, handle-invalid=DONT-INVALIDATE}
      data tec_OBCMgmt_ElectcLockCtrlSts_Enum: type=uint8
    IF_OBCMgmt_ElectcLockStatErrDTC_8bit: invalidation-policy{data-element=tec_OBCMgmt_ElectcLockStatErrDTC_8bit, handle-invalid=DONT-INVALIDATE}
      data tec_OBCMgmt_ElectcLockStatErrDTC_8bit: type=uint8
    IF_OBCMgmt_MnyUnlckCmt_Enum: invalidation-policy{data-element=tec_OBCMgmt_MnyUnlckCmt_Enum, handle-invalid=DONT-INVALIDATE}
      data tec_OBCMgmt_MnyUnlckCmt_Enum: type=uint8
    IF_OBCMgmt_OBCCtrlErrDTC_8bit: invalidation-policy{data-element=tec_OBCMgmt_OBCCtrlErrDTC_8bit, handle-invalid=DONT-INVALIDATE}
      data tec_OBCMgmt_OBCCtrlErrDTC_8bit: type=uint8
    IF_OBCMgmt_OBCEnaCmd_Enum: invalidation-policy{data-element=tec_OBCMgmt_OBCEnaCmd_Enum, handle-invalid=DONT-INVALIDATE}
      data tec_OBCMgmt_OBCEnaCmd_Enum: type=uint8
    IF_OBCMgmt_OBCOutpCpbyIDc_A: invalidation-policy{data-element=tec_OBCMgmt_OBCOutpCpbyIDc_A, handle-invalid=DONT-INVALIDATE}
      data tec_OBCMgmt_OBCOutpCpbyIDc_A: type=float32
    IF_OBCMgmt_ReqOBCIDc_A: invalidation-policy{data-element=tec_OBCMgmt_ReqOBCIDc_A, handle-invalid=DONT-INVALIDATE}
      data tec_OBCMgmt_ReqOBCIDc_A: type=float32
    IF_OBCMgmt_S2SwtCtrlCmd_Enum: invalidation-policy{data-element=tec_OBCMgmt_S2SwtCtrlCmd_Enum, handle-invalid=DONT-INVALIDATE}
      data tec_OBCMgmt_S2SwtCtrlCmd_Enum: type=uint8
    IF_OBCMgmt_S2SwtCtrlErrDTC_8bit: invalidation-policy{data-element=tec_OBCMgmt_S2SwtCtrlErrDTC_8bit, handle-invalid=DONT-INVALIDATE}
      data tec_OBCMgmt_S2SwtCtrlErrDTC_8bit: type=uint8
    IF_OBCMgmt_S2SwtCtrlSts_Enum: invalidation-policy{data-element=tec_OBCMgmt_S2SwtCtrlSts_Enum, handle-invalid=DONT-INVALIDATE}
      data tec_OBCMgmt_S2SwtCtrlSts_Enum: type=uint8
